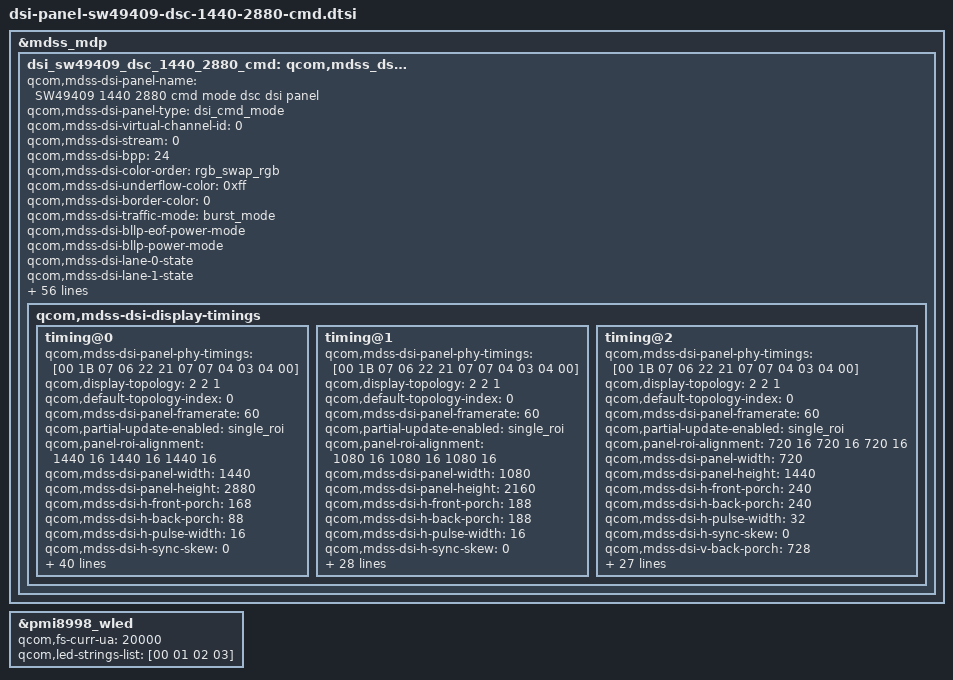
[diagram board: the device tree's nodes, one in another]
/* Copyright (c) 2014, Code Aurora Forum. All rights reserved.
 *
 * This program is free software; you can redistribute it and/or modify
 * it under the terms of the GNU General Public License version 2 and
 * only version 2 as published by the Free Software Foundation.
 *
 * This program is distributed in the hope that it will be useful,
 * but WITHOUT ANY WARRANTY; without even the implied warranty of
 * MERCHANTABILITY or FITNESS FOR A PARTICULAR PURPOSE.  See the
 * GNU General Public License for more details.
 */

&mdss_mdp {
	dsi_sw49409_dsc_1440_2880_cmd: qcom,mdss_dsi_sw49409_dsc_1440_2880_cmd {
		qcom,mdss-dsi-panel-name = "SW49409 1440 2880 cmd mode dsc dsi panel";
		qcom,mdss-dsi-panel-type = "dsi_cmd_mode";
		qcom,mdss-dsi-virtual-channel-id = <0>;
		qcom,mdss-dsi-stream = <0>;
		qcom,mdss-dsi-bpp = <24>;
		qcom,mdss-dsi-color-order = "rgb_swap_rgb";
		qcom,mdss-dsi-underflow-color = <0xff>;
		qcom,mdss-dsi-border-color = <0>;

		qcom,mdss-dsi-traffic-mode = "burst_mode";
		qcom,mdss-dsi-bllp-eof-power-mode;
		qcom,mdss-dsi-bllp-power-mode;
//		qcom,partial-update-enabled;
		qcom,mdss-dsi-lane-0-state;
		qcom,mdss-dsi-lane-1-state;
		qcom,mdss-dsi-lane-2-state;
		qcom,mdss-dsi-lane-3-state;
		qcom,mdss-dsi-reset-sequence = <1 10>, <0 10>, <1 10>;
		qcom,mdss-dsi-bl-max-level = <4095>;
		qcom,adjust-timer-wakeup-ms = <1>;
		qcom,mdss-dsi-dma-trigger = "trigger_sw";
		qcom,mdss-dsi-mdp-trigger = "none";
		qcom,mdss-dsi-te-pin-select = <1>;
		qcom,mdss-dsi-wr-mem-start = <0x2c>;
		qcom,mdss-dsi-wr-mem-continue = <0x3c>;
		qcom,mdss-dsi-te-dcs-command = <1>;
		qcom,mdss-dsi-te-check-enable;
		qcom,mdss-dsi-te-using-te-pin;
//		qcom,ulps-enabled;
		qcom,suspend-ulps-enabled;
		qcom,mdss-dsi-lp11-init;
		qcom,mdss-dsi-tx-eot-append;
		//qcom,esd-check-enabled;
		//qcom,mdss-dsi-panel-status-check-mode = "te_signal_check";
//		qcom,mdss-mdp-transfer-time-us = <15200>;
		lge,drs-mngr-enabled;
		lge,use-mplus;
		lge,use-hl-mode;
		lge,incell-panel;
		lge,use-color-manager;
		lge,use-ambient;
		lge,aod-interface-data = <0x144>; /* QHD = 1, FHD = 4, HD = 4 */

		qcom,mdss-dsi-panel-hdr-enabled;
		qcom,mdss-dsi-panel-hdr-color-primaries = <14649 15851 33084 15473 13806 31961 7476 2719>;
		qcom,mdss-dsi-panel-peak-brightness = <5000000>;	/* max. 500nits */
		qcom,mdss-dsi-panel-blackness-level = <3022>;

		lge,blmap = <
			0
			16 16 16 16 16 16 16 16 16 16
			16 16 17 17 17 17 18 18 18 18
			19 19 19 20 21 22 23 24 25 26
			27 28 29 30 32 34 35 37 39 40
			42 44 46 47 49 51 52 54 57 59
			62 64 67 69 72 74 77 79 82 87
			91 94 98 101 105 108 112 115 119 122
			126 133 137 142 146 151 155 160 164 169
			173 178 182 191 196 202 207 213 218 224
			229 235 240 246 251 257 262 268 275 281
			288 294 300 307 313 319 326 332 345 353
			360 368 376 383 391 399 407 414 422 430
			445 453 461 469 477 485 493 502 510 518
			526 534 550 559 569 575 588 597 606 616
			625 634 644 653 663 672 682 693 703 713
			724 734 744 754 765 775 785 806 817 829
			840 852 863 875 886 898 909 921 932 955
			968 980 993 1006 1018 1031 1044 1057 1069 1082
			1095 1120 1134 1148 1162 1175 1189 1203 1217 1231
			1245 1258 1272 1286 1300 1315 1331 1346 1362 1377
			1392 1408 1423 1438 1454 1469 1500 1516 1532 1548
			1565 1581 1597 1613 1629 1645 1662 1678 1710 1728
			1746 1764 1782 1800 1818 1837 1855 1873 1891 1909
			1945 1965 1984 2004 2023 2043 2063 2082 2102 2122
			2141 2161 2180 2200 2220 2240 2260 2279 2299 2319
			2339 2359 2379 2398 2458
		>;

		lge,blmap-ps = <
			0
			16 16 16 16 16 16 16 16 16 16
			16 16 16 17 17 17 17 17 17 18
			18 18 18 19 20 20 21 22 23 23
			24 25 26 26 27 28 30 31 33 34
			36 37 39 40 42 43 45 46 48 51
			53 56 58 61 63 65 68 70 73 75
			78 82 85 88 92 95 98 102 105 108
			112 115 119 123 126 130 134 138 141 145
			149 153 156 160 165 169 174 178 183 188
			192 197 202 206 211 215 220 226 232 238
			243 249 255 261 267 273 278 284 290 297
			303 310 317 323 330 337 343 350 357 363
			370 378 386 394 402 410 418 425 433 441
			449 457 465 473 480 488 496 503 511 519
			527 534 542 550 557 565 574 583 593 602
			611 620 629 638 648 657 666 675 685 696
			706 717 727 738 748 758 769 779 790 800
			812 823 835 847 858 870 882 893 905 917
			928 940 952 963 975 986 998 1009 1021 1032
			1044 1055 1067 1078 1090 1104 1118 1131 1145 1159
			1173 1186 1200 1214 1228 1241 1255 1270 1285 1300
			1315 1330 1345 1360 1375 1390 1405 1420 1435 1452
			1468 1485 1502 1518 1535 1552 1568 1585 1602 1618
			1635 1650 1666 1681 1697 1712 1727 1743 1758 1773
			1789 1804 1820 1835 1856 1877 1897 1918 1939 1960
			1981 2002 2022 2043 2064
		>;

		lge,blmap-hq = <
			0
			16 16 16 16 16 16 16 16 16 16
			16 17 17 17 18 18 18 18 19 19
			19 20 20 21 22 24 25 26 27 28
			29 31 32 33 34 36 38 40 42 44
			46 47 49 51 53 55 57 59 62 66
			69 72 75 79 82 85 88 92 95 98
			102 107 111 115 120 124 128 133 137 141
			146 150 156 161 167 172 178 184 189 195
			200 206 211 217 223 229 236 242 248 254
			261 267 273 279 286 292 298 306 314 322
			330 338 346 353 361 369 377 385 393 402
			412 421 430 440 449 458 468 477 486 496
			505 515 525 536 546 556 566 576 586 597
			607 617 627 638 649 660 670 681 692 703
			714 725 735 746 757 768 781 794 807 820
			833 846 859 872 885 898 911 924 939 953
			968 982 997 1011 1026 1040 1055 1069 1084 1098
			1114 1130 1146 1162 1178 1194 1210 1226 1242 1258
			1274 1290 1306 1322 1338 1355 1371 1387 1403 1419
			1435 1452 1468 1484 1500 1519 1538 1558 1577 1596
			1615 1634 1653 1673 1692 1711 1730 1751 1772 1793
			1813 1834 1855 1876 1897 1918 1938 1959 1980 2003
			2025 2048 2070 2093 2115 2138 2160 2183 2205 2228
			2250 2273 2295 2318 2341 2363 2386 2409 2432 2454
			2477 2500 2522 2545 2574 2602 2631 2660 2688 2717
			2745 2774 2803 2831 2860
		>;

		lge,blmap-hl = <
			0
			2459 2460 2460 2461 2462 2462 2463 2463 2464 2465
			2465 2466 2467 2467 2468 2469 2469 2470 2470 2471
			2472 2472 2473 2474 2474 2475 2475 2476 2477 2477
			2478 2479 2479 2480 2481 2481 2482 2482 2483 2484
			2484 2485 2486 2486 2487 2488 2488 2489 2489 2490
			2491 2491 2492 2493 2493 2494 2494 2495 2496 2496
			2497 2498 2498 2499 2500 2500 2501 2501 2502 2503
			2503 2504 2505 2505 2506 2507 2507 2508 2508 2509
			2510 2510 2511 2512 2512 2513 2514 2514 2515 2515
			2516 2517 2517 2518 2519 2519 2520 2520 2521 2522
			2522 2523 2524 2524 2525 2526 2526 2527 2527 2528
			2529 2529 2530 2531 2531 2532 2533 2533 2534 2534
			2535 2536 2536 2537 2538 2538 2539 2540 2540 2541
			2541 2542 2543 2543 2544 2545 2545 2546 2546 2547
			2548 2548 2549 2550 2550 2551 2552 2552 2553 2553
			2554 2555 2555 2556 2557 2557 2558 2559 2559 2560
			2560 2561 2562 2562 2563 2564 2564 2565 2565 2566
			2567 2567 2568 2569 2569 2570 2571 2571 2572 2572
			2573 2574 2574 2575 2576 2576 2577 2578 2578 2579
			2579 2580 2581 2581 2582 2583 2583 2584 2585 2585
			2586 2586 2587 2588 2588 2589 2590 2590 2591 2591
			2592 2593 2593 2594 2595 2595 2596 2597 2597 2598
			2598 2599 2600 2600 2601 2602 2602 2603 2604 2604
			2605 2605 2606 2607 2607 2608 2609 2609 2610 2610
			2611 2612 2612 2613 2614 2614 2615 2616 2616 2617
			2617 2618 2619 2619 2620
		>;

		lge,blmap-ps-hl = <
			0
			2065 2067 2069 2072 2074 2076 2078 2080 2082 2085
			2087 2089 2091 2093 2096 2098 2100 2102 2104 2107
			2109 2111 2113 2115 2117 2120 2122 2124 2126 2128
			2131 2133 2135 2137 2139 2141 2144 2146 2148 2150
			2152 2155 2157 2159 2161 2163 2166 2168 2170 2172
			2174 2176 2179 2181 2183 2185 2187 2190 2192 2194
			2196 2198 2200 2203 2205 2207 2209 2211 2214 2216
			2218 2220 2222 2225 2227 2229 2231 2233 2235 2238
			2240 2242 2244 2246 2249 2251 2253 2255 2257 2259
			2262 2264 2266 2268 2270 2273 2275 2277 2279 2281
			2284 2286 2288 2290 2292 2294 2297 2299 2301 2303
			2305 2308 2310 2312 2314 2316 2318 2321 2323 2325
			2327 2329 2332 2334 2336 2338 2340 2343 2345 2347
			2349 2351 2353 2356 2358 2360 2362 2364 2367 2369
			2371 2373 2375 2377 2380 2382 2384 2386 2388 2391
			2393 2395 2397 2399 2401 2404 2406 2408 2410 2412
			2415 2417 2419 2421 2423 2426 2428 2430 2432 2434
			2436 2439 2441 2443 2445 2447 2450 2452 2454 2456
			2458 2460 2463 2465 2467 2469 2471 2474 2476 2478
			2480 2482 2485 2487 2489 2491 2493 2495 2498 2500
			2502 2504 2506 2509 2511 2513 2515 2517 2519 2522
			2524 2526 2528 2530 2533 2535 2537 2539 2541 2544
			2546 2548 2550 2552 2554 2557 2559 2561 2563 2565
			2568 2570 2572 2574 2576 2578 2581 2583 2585 2587
			2589 2592 2594 2596 2598 2600 2603 2605 2607 2609
			2611 2613 2616 2618 2620
		>;

		lge,blmap-hb-hd = <
			0
			1 1 1 1 1 1 1 1 1 1
			12 22 33 44 54 65 76 87 97 108
			119 129 140 151 161 172 183 193 204 215
			225 236 247 258 268 279 290 300 311 322
			332 343 354 364 375 386 397 407 418 429
			439 450 461 471 482 493 503 514 525 535
			546 557 568 578 589 600 610 621 632 642
			653 664 674 685 696 707 717 728 739 749
			760 771 781 792 803 813 824 835 845 856
			867 878 888 899 910 920 931 942 952 963
			974 984 995 1006 1017 1027 1038 1049 1059 1070
			1081 1091 1102 1113 1123 1134 1145 1155 1166 1177
			1188 1198 1209 1220 1230 1241 1252 1262 1273 1284
			1294 1305 1316 1327 1337 1348 1359 1369 1380 1391
			1401 1412 1423 1433 1444 1455 1466 1476 1487 1498
			1508 1519 1530 1540 1551 1562 1572 1583 1594 1604
			1615 1626 1637 1647 1658 1669 1679 1690 1701 1711
			1722 1733 1743 1754 1765 1776 1786 1797 1808 1818
			1829 1840 1850 1861 1872 1882 1893 1904 1914 1925
			1936 1947 1957 1968 1979 1989 2000 2011 2021 2032
			2043 2053 2064 2075 2086 2096 2107 2118 2128 2139
			2150 2160 2171 2182 2192 2203 2214 2224 2235 2246
			2257 2267 2278 2289 2299 2310 2321 2331 2342 2353
			2363 2374 2385 2396 2406 2417 2428 2438 2449 2460
			2470 2481 2492 2502 2513 2524 2534 2545 2556 2567
			2577 2588 2599 2609 2620
		>;

		lge,blmap-ex = <
			0
			70 70 70 70 70 70 70 70 70 70
			70 71 71 71 72 72 72 72 73 73
			73 74 74 75 76 78 79 80 81 82
			83 85 86 87 88 89 90 91 93 94
			95 96 97 98 99 101 102 103 104 105
			107 108 109 110 112 113 114 115 117 118
			119 120 121 123 124 125 126 127 128 130
			131 132 133 134 135 142 148 155 162 168
			175 181 188 195 201 208 215 221 228 234
			241 248 254 261 268 274 281 287 294 301
			307 314 321 327 334 340 347 354 360 367
			374 380 387 393 400 403 406 409 412 415
			418 421 424 427 430 433 436 439 442 445
			448 451 454 457 460 463 466 469 472 475
			478 481 484 487 490 493 496 499 502 505
			508 511 514 517 520 523 526 529 532 535
			538 541 544 547 550 553 556 559 562 565
			568 571 574 577 580 583 586 589 592 595
			598 601 604 607 610 613 616 619 622 625
			628 631 634 637 640 643 646 649 652 655
			658 661 664 667 670 673 676 679 682 685
			688 691 694 697 700 703 706 709 712 715
			718 721 724 727 730 733 736 739 742 745
			748 751 754 757 760 763 766 769 772 775
			778 781 784 787 790 793 796 799 802 805
			808 811 814 817 820
		>;

		qcom,mdss-pan-physical-width-dimension = <65>;
		qcom,mdss-pan-physical-height-dimension = <130>;

		qcom,mdss-dsi-t-clk-post = <0x0D>;
		qcom,mdss-dsi-t-clk-pre = <0x2B>;

		lge,mdss-dsi-ddic-mplus-command = [39 01 00 00 00 00 0B D3 40 07 62 46 6F 27 F1 80 FE FA];
		lge,mdss-dsi-ddic-mplus-command-state = "dsi_hs_mode";

		lge,mdss-dsi-lp2-command = [
			/* Partial Area */
			39 01 00 00 00 00 05 30 00 00 03 83
			/* U2 Control */
			39 01 00 00 00 00 12 CD 00 A1 02 80 00 00 00 00 00 08 00 F0 00 00 00 00 00
			/* Partial Mode ON  + min 55ms*/
			05 01 00 00 37 00 01 12
		];
		lge,mdss-dsi-lp2-command-state = "dsi_lp_mode";

		lge,mdss-dsi-nolp-command = [
			/* U2 Control */
			39 01 00 00 00 00 12 CD 09 A6 12 80 00 00 00 00 00 00 00 00 00 14 00 00 00
			/* Normal Mode ON + min 40ms*/
			05 01 00 00 28 00 01 13
		];
		lge,mdss-dsi-nolp-command-state = "dsi_lp_mode";

		qcom,mdss-dsi-display-timings {
			timing@0{
				qcom,mdss-dsi-panel-phy-timings = [00 1B 07 06 22 21 07 07 04 03 04 00];
				qcom,display-topology = <2 2 1>;
				qcom,default-topology-index = <0>;
				qcom,mdss-dsi-panel-framerate = <60>;
				qcom,partial-update-enabled = "single_roi";
				qcom,panel-roi-alignment = <1440 16 1440 16 1440 16>;
				qcom,mdss-dsi-panel-width = <1440>;
				qcom,mdss-dsi-panel-height = <2880>;
				qcom,mdss-dsi-h-front-porch = <168>;
				qcom,mdss-dsi-h-back-porch = <88>;
				qcom,mdss-dsi-h-pulse-width = <16>;
				qcom,mdss-dsi-h-sync-skew = <0>;
				qcom,mdss-dsi-v-back-porch = <10>;
				qcom,mdss-dsi-v-front-porch = <9>;
				qcom,mdss-dsi-v-pulse-width = <1>;
				qcom,mdss-dsi-h-left-border = <0>;
				qcom,mdss-dsi-h-right-border = <0>;
				qcom,mdss-dsi-v-top-border = <0>;
				qcom,mdss-dsi-v-bottom-border = <0>;
				qcom,mdss-dsi-h-sync-pulse = <0>;

				qcom,mdss-dsi-on-command = [
					/* TE On */
					15 01 00 00 00 00 02 35 00
					/* Page Address Set */
					39 01 00 00 00 00 05 2B 00 00 0B 3F
					/* BLU Control */
					15 01 00 00 00 00 02 51 FF
					15 01 00 00 00 00 02 53 2C
					15 01 00 00 00 00 02 5E 00
					/* IE, SRE, CABC */
					15 01 00 00 00 00 02 55 80
					/* Manufacture Protection */
					15 01 00 00 00 00 02 B0 AC
					/* Source Control */
					39 01 00 00 00 00 08 B3 08 07 28 08 1A 23 02
					/* Gate & Mux Control */
					39 01 00 00 00 00 20 B4 11 04 02 02 02 02 02 00 00 00 00 00 00 90 11 44 E4 1B 1B E4 0A 18 08 25 2A 00 00 00 00 00 00
					/* Sync Setup */
 					39 01 00 00 00 00 09 B5 53 0F 10 C0 00 10 C0 00
					/* Panel Setting */
					39 01 00 00 00 00 06 B6 03 05 CF F2 2C
					/* Touch Timing Control */
					39 01 00 00 00 00 20 B8 17 02 90 40 55 50 09 00 00 18 33 04 01 00 01 44 CF C0 17 00 00 10 33 04 01 0A 00 30 0A 40 9C
					/* Touch Source Setting */
					39 01 00 00 00 00 06 B9 64 64 2A 3F EE
					/* Internal Oscillator Setting */
					39 01 00 00 00 00 04 C0 91 05 0A
					/* Power Control1 */
					39 01 00 00 00 00 07 C1 01 00 F0 E2 CF 0C
					/* Power Control2 */
					39 01 00 00 00 00 09 C2 CC 44 44 40 22 26 21 00
					/* Power Control3 */
					39 01 00 00 00 00 12 C3 92 91 09 09 91 CC 0A A4 A4 02 A2 38 28 14 13 13 E0
					/* Vcom Setting */
					39 01 00 00 00 00 03 C4 0F 01
					/* Power Sequence Option Configuration */
					39 01 00 00 00 00 06 C9 05 5D 03 04 00
					/* Abrupt Power Off Control */
					39 01 00 00 00 00 03 CA 1B 10
					/* LFD Control */
					39 01 00 00 00 00 06 CB F3 90 3D 30 CC
					/* Tail TFT Setting */
					39 01 00 00 00 00 06 CC 14 50 50 90 41
					/* Gamma */
					39 01 00 00 00 00 79 D0 00 00 0B 0B 1A 1A 3F 3F 4F 4F 66 66 73 73 82 82 36 36 9D 9D 8C 8C 72 72 55 55 3B 3B 00 00 00 00 0B 0B 1A 1A 3F 3F 4F 4F 66 66 73 73 82 82 36 36 9D 9D 8C 8C 72 72 55 55 3B 3B 00 00 00 00 0B 0B 1A 1A 3F 3F 4F 4F 66 66 73 73 82 82 36 36 9D 9D 8C 8C 72 72 55 55 3B 3B 00 00 00 00 0B 0B 1A 1A 3F 3F 4F 4F 66 66 73 73 82 82 36 36 9D 9D 8C 8C 72 72 55 55 3B 3B 00 00
					39 01 00 00 00 00 79 D1 00 00 0E 0E 1D 1D 42 42 52 52 66 66 73 73 82 82 36 36 9D 9D 8C 8C 72 72 56 56 3C 3C 00 00 00 00 0E 0E 1D 1D 42 42 52 52 66 66 73 73 82 82 36 36 9D 9D 8C 8C 72 72 56 56 3C 3C 00 00 00 00 0E 0E 1D 1D 42 42 52 52 66 66 73 73 82 82 36 36 9D 9D 8C 8C 72 72 56 56 3C 3C 00 00 00 00 0E 0E 1D 1D 42 42 52 52 66 66 73 73 82 82 36 36 9D 9D 8C 8C 72 72 56 56 3C 3C 00 00
					39 01 00 00 00 00 79 D2 00 00 0E 0E 1D 1D 42 42 52 52 66 66 73 73 82 82 36 36 9D 9D 8C 8C 72 72 56 56 3C 3C 00 00 00 00 0E 0E 1D 1D 42 42 52 52 66 66 73 73 82 82 36 36 9D 9D 8C 8C 72 72 56 56 3C 3C 00 00 00 00 0E 0E 1D 1D 42 42 52 52 66 66 73 73 82 82 36 36 9D 9D 8C 8C 72 72 56 56 3C 3C 00 00 00 00 0E 0E 1D 1D 42 42 52 52 66 66 73 73 82 82 36 36 9D 9D 8C 8C 72 72 56 56 3C 3C 00 00
					/* Test1 */
					39 01 00 00 00 00 06 ED 21 68 00 90 00
					/* SAT, GC, SH */
					15 01 00 00 00 00 02 F0 82
					/* MIE register SH Strength */
					39 01 00 00 00 00 05 F2 01 00 18 00
					/* MIE register */
					39 01 00 00 00 00 07 F3 00 43 8B D0 00 01
					/* BLU Control */
					39 01 00 00 00 00 18 FA 20 40 60 80 A0 C0 E0 15 13 0F 0F 0C 03 02 00 D9 DE E2 E7 EC F5 FA FF
					/* BLU PWM Control */
					39 01 00 00 00 00 0E FB 21 70 D0 04 40 7B 02 FF 12 22 22 10 00
					/* GIP Setting */
					39 01 00 00 00 00 1B E5 0B 0A 0C 00 02 04 06 08 0F 1B 00 1A 1A 0B 0A 0C 01 03 05 07 09 10 1B 01 1A 1A
					/* MUX Setting */
					39 01 00 00 00 00 11 E6 11 12 13 14 17 18 15 16 11 12 13 14 17 18 15 16
				];
				qcom,mdss-dsi-post-panel-on-command = [
					/* Normal Display mode on */
					05 01 00 00 00 00 01 13
					/* Sleep Out + min 120ms */
					05 01 00 00 80 00 01 11
					/* Manufacture Protection */
					15 01 00 00 00 00 02 B0 AC
					/* MPLUS Control */
					39 01 00 00 00 00 0B D3 40 07 62 46 6F 27 F1 80 FE FA
					/* Original RGBW */
					39 01 00 00 00 00 A1 D4 DC 7C 9C 1C 0E AA 0E AA 0E AA 11 56 11 75 11 75 11 75 0E C4 00 02 00 00 02 00 00 02 00 00 02 00 00 1F A4 00 00 0C A8 00 00 1F A4 00 00 0C A8 00 00 1F A4 00 00 0C A8 00 00 1F A4 00 00 0C A8 00 00 00 00 00 18 00 22 DC 22 DC 22 DC 06 06 06 06 01 00 3f ff 00 90 01 80 00 90 12 DC 12 DC 12 DC 12 DC 10 10 10 10 22 DC FF FF 16 66 18 00 16 66 10 00 FF 01 00 02 00 03 00 04 00 05 00 06 00 07 00 08 00 09 00 0A 00 0B 00 0C 00 0D 00 0E 00 0F 00 1B 25 DC 18 00 20 00 30 00 08 80 20 00 10 00
					/* Round Algorithm */
					39 01 00 00 00 00 A1 D5 0F 12 0F 0D 08 08 08 08 06 05 06 05 06 04 05 04 04 04 04 05 03 03 04 03 04 03 03 03 03 03 02 03 03 02 03 03 03 02 02 02 03 02 02 02 03 02 02 02 02 02 02 01 02 02 02 02 01 02 02 02 01 02 01 02 01 01 02 01 02 01 02 01 02 01 01 01 01 02 01 01 01 01 02 01 01 01 01 01 01 01 01 01 01 01 01 01 02 02 01 01 01 02 02 01 01 02 02 01 02 02 01 01 02 02 02 02 02 02 02 02 02 02 02 02 02 02 02 02 02 02 02 02 04 04 04 04 04 04 04 04 04 04 04 04 05 05 05 05 05 05 05 05 05 05 06 06 06 06 06 06
					/* Notch Algorithm */
					39 01 00 00 00 00 A1 D5 1F 1F 1F 1F 1F 1F 1F 1F 1F 1F 1F 1F 1F 1F 1F 1F 1F 1F 1F 1F 1F 1F 1F 1F 1F 1F 1F 1F 1F 1F 1F 1F 1F 1F 1F 1F 1F 1F 1F 1F 1F 1F 1F 1F 1F 1F 1F 1F 1F 1F 1F 1F 1F 1F 1F 1F 1F 1F 1F 1F 1F 1F 1F 1F 1F 1F 1F 1F 1F 1F 05 05 05 05 05 03 03 03 02 02 03 03 03 02 02 02 02 01 02 02 02 02 01 02 02 01 01 01 02 02 01 01 01 01 01 01 01 01 01 01 01 02 01 01 01 02 01 02 01 02 01 02 01 02 02 01 02 02 02 02 02 02 02 02 02 03 02 02 03 03 02 03 03 03 03 03 04 04 03 04 05 04 05 05 06 07 07 09 0B 1D
					/* ACM Off */
					39 01 00 00 00 00 3B E8 E0 eA 67 C1 7F 03 80 7F FE F9 0F 00 74 41 E6 07 0E 73 C2 D4 A7 F9 1F 00 1C AE 3F 10 00 04 20 00 00 00 00 Ac 84 95 B0 12 00 50 F2 F5 50 CC E9 EE 00 00 00 00 00 00 F0 01 0C 60
					/* Display On */
					05 01 00 00 40 00 01 29
				];
				qcom,mdss-dsi-off-command = [
					/* Display Off */
					05 01 00 00 00 00 01 28
					/* Sleep In + min 90ms */
					05 01 00 00 5A 00 01 10
				];

				qcom,mdss-dsi-on-command-state = "dsi_lp_mode";
				qcom,mdss-dsi-off-command-state = "dsi_hs_mode";

				qcom,compression-mode = "dsc";
				qcom,mdss-dsc-version = <0x11>;
				qcom,mdss-dsc-scr-version = <0x1>;
				qcom,lm-split = <0 0>;
				qcom,mdss-dsc-encoders = <2>;
				qcom,mdss-dsc-slice-height = <16>;
				qcom,mdss-dsc-slice-width = <720>;
				qcom,mdss-dsc-slice-per-pkt = <2>;
				qcom,mdss-dsc-bit-per-component = <10>;
				qcom,mdss-dsc-bit-per-pixel = <8>;
				qcom,mdss-dsc-block-prediction-enable;
				qcom,mdss-dsi-pps-command-state = "dsi_hs_mode";
				lge,mdss-dsi-color-manager-mode-table = <3 1>, <0 1>, <2 1>, <1 1>;

				lge,mdss-dsi-disp-ctrl-command-1 = [
					15 01 00 00 00 00 02 53 2C
				];
				lge,mdss-dsi-disp-ctrl-command-1-state = "dsi_hs_mode";
				lge,mdss-dsi-disp-ctrl-command-2 = [
					15 01 00 00 00 00 02 55 81
				];
				lge,mdss-dsi-disp-ctrl-command-2-state = "dsi_hs_mode";

				lge,digital-gamma-cmds-dummy = [
					39 00 00 00 00 00 11 F4 00 00 00 00 00 00 00 00 00 00 00 00 00 00 00 00
					39 00 00 00 00 00 11 F5 00 00 00 00 00 00 00 00 00 00 00 00 00 00 00 00
					39 00 00 00 00 00 11 F6 00 00 00 00 00 00 00 00 00 00 00 00 00 00 00 00
				];
			};
			timing@1{
				qcom,mdss-dsi-panel-phy-timings = [00 1B 07 06 22 21 07 07 04 03 04 00];
				qcom,display-topology = <2 2 1>;
				qcom,default-topology-index = <0>;
				qcom,mdss-dsi-panel-framerate = <60>;
				qcom,partial-update-enabled = "single_roi";
				qcom,panel-roi-alignment = <1080 16 1080 16 1080 16>;
				qcom,mdss-dsi-panel-width = <1080>;
				qcom,mdss-dsi-panel-height = <2160>;
				qcom,mdss-dsi-h-front-porch = <188>;
				qcom,mdss-dsi-h-back-porch = <188>;
				qcom,mdss-dsi-h-pulse-width = <16>;
				qcom,mdss-dsi-h-sync-skew = <0>;
				qcom,mdss-dsi-v-back-porch = <450>;
				qcom,mdss-dsi-v-front-porch = <289>;
				qcom,mdss-dsi-v-pulse-width = <1>;
				qcom,mdss-dsi-h-left-border = <0>;
				qcom,mdss-dsi-h-right-border = <0>;
				qcom,mdss-dsi-v-top-border = <0>;
				qcom,mdss-dsi-v-bottom-border = <0>;
				qcom,mdss-dsi-h-sync-pulse = <0>;

				qcom,mdss-dsi-on-command = [
					/* TE On */
					15 01 00 00 00 00 02 35 00
					/* Page Address Set */
					39 01 00 00 00 00 05 2B 00 00 0B 3F
					/* BLU Control */
					15 01 00 00 00 00 02 51 FF
					15 01 00 00 00 00 02 53 2C
					15 01 00 00 00 00 02 5E 00
					/* IE, SRE, CABC */
					15 01 00 00 00 00 02 55 80
					/* Manufacture Protection */
					15 01 00 00 00 00 02 B0 AC
					/* Source Control */
					39 01 00 00 00 00 08 B3 08 07 28 08 1A 23 02
					/* Gate & Mux Control */
					39 01 00 00 00 00 20 B4 11 04 02 02 02 02 02 00 00 00 00 00 00 90 11 44 E4 1B 1B E4 0A 18 08 25 2A 00 00 00 00 00 00
					/* Sync Setup */
					39 01 00 00 00 00 09 B5 53 0F 10 C0 00 10 C0 00
					/* Panel Setting */
					39 01 00 00 00 00 06 B6 03 05 CF F2 2C
					/* Touch Timing Control */
					39 01 00 00 00 00 20 B8 17 02 90 40 55 50 09 00 00 18 33 04 01 00 01 44 CF C0 17 00 00 10 33 04 01 0A 00 30 0A 40 9C
					/* Touch Source Setting */
					39 01 00 00 00 00 06 B9 64 64 2A 3F EE
					/* Internal Oscillator Setting */
					39 01 00 00 00 00 04 C0 91 05 0A
					/* Power Control1 */
					39 01 00 00 00 00 07 C1 01 00 F0 E2 CF 0C
					/* Power Control2 */
					39 01 00 00 00 00 09 C2 CC 44 44 40 22 26 21 00
					/* Power Control3 */
					39 01 00 00 00 00 12 C3 92 91 09 09 91 CC 0A A4 A4 02 A2 38 28 14 13 13 E0
					/* Vcom Setting */
					39 01 00 00 00 00 03 C4 0F 01
					/* Power Sequence Option Configuration */
					39 01 00 00 00 00 06 C9 05 5D 03 04 00
					/* Abrupt Power Off Control */
					39 01 00 00 00 00 03 CA 1B 10
					/* LFD Control */
					39 01 00 00 00 00 06 CB F3 90 3D 30 CC
					/* Tail TFT Setting */
					39 01 00 00 00 00 06 CC 14 50 50 90 41
					/* Gamma */
					39 01 00 00 00 00 79 D0 00 00 0E 0E 1D 1D 42 42 52 52 66 66 73 73 82 82 36 36 9D 9D 8C 8C 72 72 56 56 3C 3C 00 00 00 00 0E 0E 1D 1D 42 42 52 52 66 66 73 73 82 82 36 36 9D 9D 8C 8C 72 72 56 56 3C 3C 00 00 00 00 0E 0E 1D 1D 42 42 52 52 66 66 73 73 82 82 36 36 9D 9D 8C 8C 72 72 56 56 3C 3C 00 00 00 00 0E 0E 1D 1D 42 42 52 52 66 66 73 73 82 82 36 36 9D 9D 8C 8C 72 72 56 56 3C 3C 00 00
					39 01 00 00 00 00 79 D1 00 00 0E 0E 1D 1D 42 42 52 52 66 66 73 73 82 82 36 36 9D 9D 8C 8C 72 72 56 56 3C 3C 00 00 00 00 0E 0E 1D 1D 42 42 52 52 66 66 73 73 82 82 36 36 9D 9D 8C 8C 72 72 56 56 3C 3C 00 00 00 00 0E 0E 1D 1D 42 42 52 52 66 66 73 73 82 82 36 36 9D 9D 8C 8C 72 72 56 56 3C 3C 00 00 00 00 0E 0E 1D 1D 42 42 52 52 66 66 73 73 82 82 36 36 9D 9D 8C 8C 72 72 56 56 3C 3C 00 00
					39 01 00 00 00 00 79 D2 00 00 0E 0E 1D 1D 42 42 52 52 66 66 73 73 82 82 36 36 9D 9D 8C 8C 72 72 56 56 3C 3C 00 00 00 00 0E 0E 1D 1D 42 42 52 52 66 66 73 73 82 82 36 36 9D 9D 8C 8C 72 72 56 56 3C 3C 00 00 00 00 0E 0E 1D 1D 42 42 52 52 66 66 73 73 82 82 36 36 9D 9D 8C 8C 72 72 56 56 3C 3C 00 00 00 00 0E 0E 1D 1D 42 42 52 52 66 66 73 73 82 82 36 36 9D 9D 8C 8C 72 72 56 56 3C 3C 00 00
					/* Test1 */
					39 01 00 00 00 00 06 ED 21 68 00 90 00
					/* SAT, GC, SH */
					15 01 00 00 00 00 02 F0 82
					/* MIE register SH Strength */
					39 01 00 00 00 00 05 F2 01 00 18 00
					/* MIE register */
					39 01 00 00 00 00 07 F3 00 43 8B D0 00 01
					/* BLU Control */
					39 01 00 00 00 00 18 FA 20 40 60 80 A0 C0 E0 20 20 20 10 0C 05 05 00 B4 C0 CD DA E8 F0 F7 FF
					/* BLU PWM Control */
					39 01 00 00 00 00 0E FB 11 89 D0 02 40 7B 02 FF 12 22 22 10 00
					/* GIP Setting */
					39 01 00 00 00 00 1B E5 0B 0A 0C 00 02 04 06 08 0F 1B 00 1A 1A 0B 0A 0C 01 03 05 07 09 10 1B 01 1A 1A
					/* MUX Setting */
					39 01 00 00 00 00 11 E6 11 12 13 14 17 18 15 16 11 12 13 14 17 18 15 16
				];
				qcom,mdss-dsi-post-panel-on-command = [
					/* Normal Display mode on */
					05 01 00 00 00 00 01 13
					/* Sleep Out + min 120ms */
					05 01 00 00 80 00 01 11
					/* Manufacture Protection */
					15 01 00 00 00 00 02 B0 AC
					/* MPLUS Control */
					39 01 00 00 00 00 0B D3 40 07 62 46 6F 27 F1 80 FE FA
					/* Original RGBW */
					39 01 00 00 00 00 A1 D4 D8 7C 9C 08 0E AA 0E AA 0E AA 11 56 11 75 11 75 11 75 0E C4 00 02 00 00 02 00 00 02 00 00 02 00 00 0C A8 00 00 0C A8 00 00 0C A8 00 00 0C A8 00 00 0C A8 00 00 0C A8 00 00 0C A8 00 00 0C A8 00 00 00 00 00 22 DC 22 DC 23 4F 23 4F 06 06 06 10 01 00 03 40 03 40 04 00 3F FF 08 00 08 00 13 4F 13 4F 10 10 10 FF 22 DC 10 00 16 66 16 66 16 66 10 00 FF 01 00 02 00 03 00 04 00 05 00 06 00 07 00 08 00 09 00 0A 00 0B 00 0C 00 0D 00 0E 00 0F 00 1B 2c 00 08 00 00 00 30 00 08 80 20 00 10 00
					/* Round Algorithm */
					39 01 00 00 00 00 A1 D5 0F 12 0F 0D 08 08 08 08 06 05 06 05 06 04 05 04 04 04 04 05 03 03 04 03 04 03 03 03 03 03 02 03 03 02 03 03 03 02 02 02 03 02 02 02 03 02 02 02 02 02 02 01 02 02 02 02 01 02 02 02 01 02 01 02 01 01 02 01 02 01 02 01 02 01 01 01 01 02 01 01 01 01 02 01 01 01 01 01 01 01 01 01 01 01 01 01 02 02 01 01 01 02 02 01 01 02 02 01 02 02 01 01 02 02 02 02 02 02 02 02 02 02 02 02 02 02 02 02 02 02 02 02 04 04 04 04 04 04 04 04 04 04 04 04 05 05 05 05 05 05 05 05 05 05 06 06 06 06 06 06
					/* Notch Algorithm */
					39 01 00 00 00 00 A1 D5 1F 1F 1F 1F 1F 1F 1F 1F 1F 1F 1F 1F 1F 1F 1F 1F 1F 1F 1F 1F 1F 1F 1F 1F 1F 1F 1F 1F 1F 1F 1F 1F 1F 1F 1F 1F 1F 1F 1F 1F 1F 1F 1F 1F 1F 1F 1F 1F 1F 1F 1F 1F 1F 1F 1F 1F 1F 1F 1F 1F 1F 1F 1F 1F 1F 1F 1F 1F 1F 1F 05 05 05 05 05 03 03 03 02 02 03 03 03 02 02 02 02 01 02 02 02 02 01 02 02 01 01 01 02 02 01 01 01 01 01 01 01 01 01 01 01 02 01 01 01 02 01 02 01 02 01 02 01 02 02 01 02 02 02 02 02 02 02 02 02 03 02 02 03 03 02 03 03 03 03 03 04 04 03 04 05 04 05 05 06 07 07 09 0B 1D
					/* ACM Off */
					39 01 00 00 00 00 3B E8 E0 eA 67 C1 7F 03 80 7F FE F9 0F 00 74 41 E6 07 0E 73 C2 D4 A7 F9 1F 00 1C AE 3F 10 00 04 20 00 00 00 00 Ac 84 95 B0 12 00 50 F2 F5 50 CC E9 EE 00 00 00 00 00 00 F0 01 0C 60
					/* Display On */
					05 01 00 00 40 00 01 29
				];
				qcom,mdss-dsi-off-command = [
					/* Display Off */
					05 01 00 00 00 00 01 28
					/* Sleep In + min 90ms */
					05 01 00 00 5A 00 01 10
				];

				qcom,mdss-dsi-on-command-state = "dsi_lp_mode";
				qcom,mdss-dsi-off-command-state = "dsi_hs_mode";

				qcom,compression-mode = "dsc";
				qcom,mdss-dsc-version = <0x11>;
				qcom,mdss-dsc-scr-version = <0x1>;
				qcom,lm-split = <0 0>;
				qcom,mdss-dsc-encoders = <2>;
				qcom,mdss-dsc-slice-height = <16>;
				qcom,mdss-dsc-slice-width = <540>;
				qcom,mdss-dsc-slice-per-pkt = <2>;
				qcom,mdss-dsc-bit-per-component = <10>;
				qcom,mdss-dsc-bit-per-pixel = <8>;
				qcom,mdss-dsc-block-prediction-enable;
				qcom,mdss-dsi-pps-command-state = "dsi_hs_mode";
			};
			timing@2{
				qcom,mdss-dsi-panel-phy-timings = [00 1B 07 06 22 21 07 07 04 03 04 00];
				qcom,display-topology = <2 2 1>;
				qcom,default-topology-index = <0>;
				qcom,mdss-dsi-panel-framerate = <60>;
				qcom,partial-update-enabled = "single_roi";
				qcom,panel-roi-alignment = <720 16 720 16 720 16>;
				qcom,mdss-dsi-panel-width = <720>;
				qcom,mdss-dsi-panel-height = <1440>;
				qcom,mdss-dsi-h-front-porch = <240>;
				qcom,mdss-dsi-h-back-porch = <240>;
				qcom,mdss-dsi-h-pulse-width = <32>;
				qcom,mdss-dsi-h-sync-skew = <0>;
				qcom,mdss-dsi-v-back-porch = <728>;
				qcom,mdss-dsi-v-front-porch = <728>;
				qcom,mdss-dsi-v-pulse-width = <4>;
				qcom,mdss-dsi-h-left-border = <0>;
				qcom,mdss-dsi-h-right-border = <0>;
				qcom,mdss-dsi-v-top-border = <0>;
				qcom,mdss-dsi-v-bottom-border = <0>;
				qcom,mdss-dsi-h-sync-pulse = <0>;

				qcom,mdss-dsi-on-command = [
					/* TE On */
					15 01 00 00 00 00 02 35 00
					/* Page Address Set */
					39 01 00 00 00 00 05 2B 00 00 0B 3F
					/* BLU Control */
					15 01 00 00 00 00 02 51 FF
					15 01 00 00 00 00 02 53 2C
					15 01 00 00 00 00 02 5E 00
					/* IE, SRE, CABC */
					15 01 00 00 00 00 02 55 80
					/* Manufacture Protection */
					15 01 00 00 00 00 02 B0 AC
					/* Source Control */
					39 01 00 00 00 00 08 B3 08 07 28 08 1A 23 02
					/* Gate & Mux Control */
					39 01 00 00 00 00 20 B4 11 04 02 02 02 02 02 00 00 00 00 00 00 90 11 44 E4 1B 1B E4 0A 18 08 25 2A 00 00 00 00 00 00
					/* Sync Setup */
					39 01 00 00 00 00 09 B5 53 0F 10 C0 00 10 C0 00
					/* Panel Setting */
					39 01 00 00 00 00 06 B6 03 05 CF F2 2C
					/* Touch Timing Control */
					39 01 00 00 00 00 20 B8 17 02 90 40 55 50 09 00 00 18 33 04 01 00 01 44 CF C0 17 00 00 10 33 04 01 0A 00 30 0A 40 9C
					/* Touch Source Setting */
					39 01 00 00 00 00 06 B9 64 64 2A 3F EE
					/* Internal Oscillator Setting */
					39 01 00 00 00 00 04 C0 91 05 0A
					/* Power Control1 */
					39 01 00 00 00 00 07 C1 01 00 F0 E2 CF 0C
					/* Power Control2 */
					39 01 00 00 00 00 09 C2 CC 44 44 40 22 26 21 00
					/* Power Control3 */
					39 01 00 00 00 00 12 C3 92 91 09 09 91 CC 0A A4 A4 02 A2 38 28 14 13 13 E0
					/* Vcom Setting */
					39 01 00 00 00 00 03 C4 0F 01
					/* Power Sequence Option Configuration */
					39 01 00 00 00 00 06 C9 05 5D 03 04 00
					/* Abrupt Power Off Control */
					39 01 00 00 00 00 03 CA 1B 10
					/* LFD Control */
					39 01 00 00 00 00 06 CB F3 90 3D 30 CC
					/* Tail TFT Setting */
					39 01 00 00 00 00 06 CC 14 50 50 90 41
					/* Gamma */
					39 01 00 00 00 00 79 D0 00 00 0E 0E 1D 1D 42 42 52 52 66 66 73 73 82 82 36 36 9D 9D 8C 8C 72 72 56 56 3C 3C 00 00 00 00 0E 0E 1D 1D 42 42 52 52 66 66 73 73 82 82 36 36 9D 9D 8C 8C 72 72 56 56 3C 3C 00 00 00 00 0E 0E 1D 1D 42 42 52 52 66 66 73 73 82 82 36 36 9D 9D 8C 8C 72 72 56 56 3C 3C 00 00 00 00 0E 0E 1D 1D 42 42 52 52 66 66 73 73 82 82 36 36 9D 9D 8C 8C 72 72 56 56 3C 3C 00 00
					39 01 00 00 00 00 79 D1 00 00 0E 0E 1D 1D 42 42 52 52 66 66 73 73 82 82 36 36 9D 9D 8C 8C 72 72 56 56 3C 3C 00 00 00 00 0E 0E 1D 1D 42 42 52 52 66 66 73 73 82 82 36 36 9D 9D 8C 8C 72 72 56 56 3C 3C 00 00 00 00 0E 0E 1D 1D 42 42 52 52 66 66 73 73 82 82 36 36 9D 9D 8C 8C 72 72 56 56 3C 3C 00 00 00 00 0E 0E 1D 1D 42 42 52 52 66 66 73 73 82 82 36 36 9D 9D 8C 8C 72 72 56 56 3C 3C 00 00
					39 01 00 00 00 00 79 D2 00 00 0E 0E 1D 1D 42 42 52 52 66 66 73 73 82 82 36 36 9D 9D 8C 8C 72 72 56 56 3C 3C 00 00 00 00 0E 0E 1D 1D 42 42 52 52 66 66 73 73 82 82 36 36 9D 9D 8C 8C 72 72 56 56 3C 3C 00 00 00 00 0E 0E 1D 1D 42 42 52 52 66 66 73 73 82 82 36 36 9D 9D 8C 8C 72 72 56 56 3C 3C 00 00 00 00 0E 0E 1D 1D 42 42 52 52 66 66 73 73 82 82 36 36 9D 9D 8C 8C 72 72 56 56 3C 3C 00 00
					/* Test1 */
					39 01 00 00 00 00 06 ED 21 68 00 90 00
					/* SAT, GC, SH */
					15 01 00 00 00 00 02 F0 82
					/* MIE register SH Strength */
					39 01 00 00 00 00 05 F2 01 00 18 00
					/* MIE register */
					39 01 00 00 00 00 07 F3 00 43 8B D0 00 01
					/* BLU Control */
					39 01 00 00 00 00 18 FA 20 40 60 80 A0 C0 E0 20 20 20 10 0C 05 05 00 B4 C0 CD DA E8 F0 F7 FF
					/* BLU PWM Control */
					39 01 00 00 00 00 0E FB 11 89 D0 02 40 7B 02 FF 12 22 22 10 00
					/* GIP Setting */
					39 01 00 00 00 00 1B E5 0B 0A 0C 00 02 04 06 08 0F 1B 00 1A 1A 0B 0A 0C 01 03 05 07 09 10 1B 01 1A 1A
					/* MUX Setting */
					39 01 00 00 00 00 11 E6 11 12 13 14 17 18 15 16 11 12 13 14 17 18 15 16
				];
				qcom,mdss-dsi-post-panel-on-command = [
					/* Normal Display mode on */
					05 01 00 00 00 00 01 13
					/* Sleep Out + min 120ms */
					05 01 00 00 80 00 01 11
					/* Manufacture Protection */
					15 01 00 00 00 00 02 B0 AC
					/* MPLUS Control */
					39 01 00 00 00 00 0B D3 40 07 62 46 6F 27 F1 80 FE FA
					/* Original RGBW */
					39 01 00 00 00 00 A1 D4 D8 7C 9C 08 0E AA 0E AA 0E AA 11 56 11 75 11 75 11 75 0E C4 00 02 00 00 02 00 00 02 00 00 02 00 00 0C A8 00 00 0C A8 00 00 0C A8 00 00 0C A8 00 00 0C A8 00 00 0C A8 00 00 0C A8 00 00 0C A8 00 00 00 00 00 22 DC 22 DC 23 4F 23 4F 06 06 06 10 01 00 03 40 03 40 04 00 3F FF 08 00 08 00 13 4F 13 4F 10 10 10 FF 22 DC 10 00 16 66 16 66 16 66 10 00 FF 01 00 02 00 03 00 04 00 05 00 06 00 07 00 08 00 09 00 0A 00 0B 00 0C 00 0D 00 0E 00 0F 00 1B 2c 00 08 00 00 00 30 00 08 80 20 00 10 00
					/* Round Algorithm */
					39 01 00 00 00 00 A1 D5 0F 12 0F 0D 08 08 08 08 06 05 06 05 06 04 05 04 04 04 04 05 03 03 04 03 04 03 03 03 03 03 02 03 03 02 03 03 03 02 02 02 03 02 02 02 03 02 02 02 02 02 02 01 02 02 02 02 01 02 02 02 01 02 01 02 01 01 02 01 02 01 02 01 02 01 01 01 01 02 01 01 01 01 02 01 01 01 01 01 01 01 01 01 01 01 01 01 02 02 01 01 01 02 02 01 01 02 02 01 02 02 01 01 02 02 02 02 02 02 02 02 02 02 02 02 02 02 02 02 02 02 02 02 04 04 04 04 04 04 04 04 04 04 04 04 05 05 05 05 05 05 05 05 05 05 06 06 06 06 06 06
					/* Notch Algorithm */
					39 01 00 00 00 00 A1 D5 1F 1F 1F 1F 1F 1F 1F 1F 1F 1F 1F 1F 1F 1F 1F 1F 1F 1F 1F 1F 1F 1F 1F 1F 1F 1F 1F 1F 1F 1F 1F 1F 1F 1F 1F 1F 1F 1F 1F 1F 1F 1F 1F 1F 1F 1F 1F 1F 1F 1F 1F 1F 1F 1F 1F 1F 1F 1F 1F 1F 1F 1F 1F 1F 1F 1F 1F 1F 1F 1F 05 05 05 05 05 03 03 03 02 02 03 03 03 02 02 02 02 01 02 02 02 02 01 02 02 01 01 01 02 02 01 01 01 01 01 01 01 01 01 01 01 02 01 01 01 02 01 02 01 02 01 02 01 02 02 01 02 02 02 02 02 02 02 02 02 03 02 02 03 03 02 03 03 03 03 03 04 04 03 04 05 04 05 05 06 07 07 09 0B 1D
					/* ACM Off */
					39 01 00 00 00 00 3B E8 E0 eA 67 C1 7F 03 80 7F FE F9 0F 00 74 41 E6 07 0E 73 C2 D4 A7 F9 1F 00 1C AE 3F 10 00 04 20 00 00 00 00 Ac 84 95 B0 12 00 50 F2 F5 50 CC E9 EE 00 00 00 00 00 00 F0 01 0C 60
					/* Display On */
					05 01 00 00 40 00 01 29
				];
				qcom,mdss-dsi-off-command = [
					/* Display Off */
					05 01 00 00 00 00 01 28
					/* Sleep In + min 90ms */
					05 01 00 00 5A 00 01 10
				];

				qcom,mdss-dsi-on-command-state = "dsi_lp_mode";
				qcom,mdss-dsi-off-command-state = "dsi_hs_mode";

				qcom,compression-mode = "dsc";
				qcom,mdss-dsc-version = <0x11>;
				qcom,mdss-dsc-scr-version = <0x1>;
				qcom,lm-split = <0 0>;
				qcom,mdss-dsc-encoders = <2>;
				qcom,mdss-dsc-slice-height = <16>;
				qcom,mdss-dsc-slice-width = <360>;
				qcom,mdss-dsc-slice-per-pkt = <2>;
				qcom,mdss-dsc-bit-per-component = <10>;
				qcom,mdss-dsc-bit-per-pixel = <8>;
				qcom,mdss-dsc-block-prediction-enable;
				qcom,mdss-dsi-pps-command-state = "dsi_hs_mode";
			};
		};
	};
};

&pmi8998_wled {
	status = "okay";
	qcom,fs-curr-ua = <20000>;
	qcom,led-strings-list = [00 01 02 03];
};
